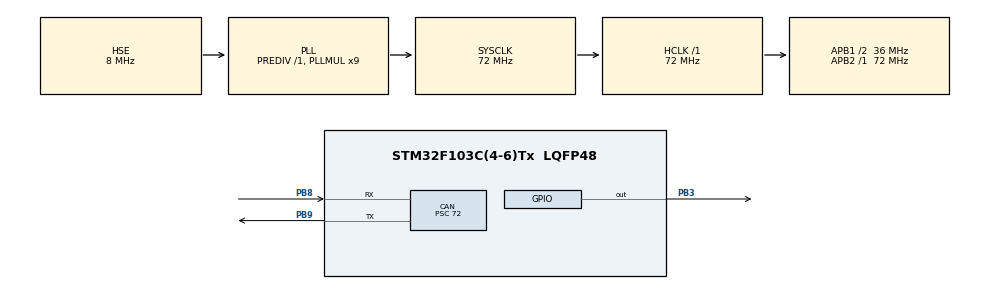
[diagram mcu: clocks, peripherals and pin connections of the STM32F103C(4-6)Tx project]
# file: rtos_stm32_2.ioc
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CAN.BS1=CAN_BS1_2TQ
CAN.CalculateBaudRate=125000
CAN.CalculateTimeBit=8000
CAN.CalculateTimeQuantum=2000.0
CAN.Prescaler=72
FREERTOS.Tasks01=receiveuart,0,128,CAN_Receive_Task,Default,NULL,Dynamic,NULL,NULL;relay2Task,0,128,Task_Relay2_Control,Default,NULL,Dynamic,NULL,NULL
FREERTOS.configUSE_NEWLIB_REENTRANT=1
Mcu.Family=STM32F1
Mcu.Name=STM32F103C(4-6)Tx
Mcu.Package=LQFP48
NVIC.CAN1_RX1_IRQn=true\:5\:0\:false\:false\:true\:true\:true\:true\:true
NVIC.PriorityGroup=NVIC_PRIORITYGROUP_4
NVIC.TIM2_IRQn=true\:15\:0\:false\:false\:true\:false\:false\:true\:true
NVIC.TimeBase=TIM2_IRQn
NVIC.TimeBaseIP=TIM2
PA13.Mode=Serial_Wire
PA13.Signal=SYS_JTMS-SWDIO
PA14.Mode=Serial_Wire
PA14.Signal=SYS_JTCK-SWCLK
PB3.Signal=GPIO_Output
PB8.Mode=CAN_Activate
PB8.Signal=CAN_RX
PB9.Mode=CAN_Activate
PB9.Signal=CAN_TX
PD0-OSC_IN.Mode=HSE-External-Oscillator
PD0-OSC_IN.Signal=RCC_OSC_IN
PD1-OSC_OUT.Mode=HSE-External-Oscillator
PD1-OSC_OUT.Signal=RCC_OSC_OUT
ProjectManager.HeapSize=0x200
ProjectManager.StackSize=0x400
ProjectManager.TargetToolchain=STM32CubeIDE
RCC.AHBFreq_Value=72000000
RCC.APB1CLKDivider=RCC_HCLK_DIV2
RCC.APB1Freq_Value=36000000
RCC.APB1TimFreq_Value=72000000
RCC.APB2Freq_Value=72000000
RCC.APB2TimFreq_Value=72000000
RCC.HCLKFreq_Value=72000000
RCC.PLLMUL=RCC_PLL_MUL9
RCC.PLLSourceVirtual=RCC_PLLSOURCE_HSE
RCC.SYSCLKFreq_VALUE=72000000
RCC.SYSCLKSource=RCC_SYSCLKSOURCE_PLLCLK
RCC.USBFreq_Value=72000000
VP_FREERTOS_VS_CMSIS_V1.Mode=CMSIS_V1
VP_SYS_VS_tim2.Mode=TIM2
board=custom

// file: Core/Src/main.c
/* USER CODE BEGIN Header */
/**
  ******************************************************************************
  * @file           : main.c
  * @brief          : Main program body
  ******************************************************************************
  * @attention
  *
  * Copyright (c) 2025 STMicroelectronics.
  * All rights reserved.
  *
  * This software is licensed under terms that can be found in the LICENSE file
  * in the root directory of this software component.
  * If no LICENSE file comes with this software, it is provided AS-IS.
  *
  ******************************************************************************
  */
/* USER CODE END Header */
#include "main.h"
#include "cmsis_os.h"
#include <string.h>

CAN_HandleTypeDef hcan;

osThreadId receiveuartHandle;
osThreadId relay2TaskHandle;
/* USER CODE BEGIN PV */
QueueHandle_t CAN_Queue;
QueueHandle_t Relay2_Queue;
/* USER CODE END PV */

void SystemClock_Config(void);
static void MX_GPIO_Init(void);
static void MX_CAN_Init(void);
void CAN_Receive_Task(void const * argument);
void Task_Relay2_Control(void const * argument);

/* USER CODE BEGIN 0 */
CAN_FilterTypeDef sFilterConfig;
CAN_RxHeaderTypeDef RxHeader;
uint8_t RxData[8];

/* Callback: CAN nhận dữ liệu */
void HAL_CAN_RxFifo1MsgPendingCallback(CAN_HandleTypeDef *hcan)
{
    if (HAL_CAN_GetRxMessage(hcan, CAN_RX_FIFO1, &RxHeader, RxData) == HAL_OK)
    {
    	BaseType_t xHigherPriorityTaskWoken = pdFALSE;
    	        xQueueSendFromISR(CAN_Queue, &RxData[0], &xHigherPriorityTaskWoken);
    	        portYIELD_FROM_ISR(xHigherPriorityTaskWoken);
    }
}
/* USER CODE END 0 */

int main(void)
{

  /* MCU Configuration--------------------------------------------------------*/

  /* Reset of all peripherals, Initializes the Flash interface and the Systick. */
  HAL_Init();

  /* Configure the system clock */
  SystemClock_Config();

  /* Initialize all configured peripherals */
  MX_GPIO_Init();
  MX_CAN_Init();
  /* USER CODE BEGIN 2 */
  HAL_GPIO_WritePin(GPIOB, GPIO_PIN_3, GPIO_PIN_SET);
  /* Khởi động CAN */
   HAL_CAN_Start(&hcan);

   /* Cấu hình bộ lọc CAN */
   sFilterConfig.FilterActivation = CAN_FILTER_ENABLE;
   sFilterConfig.FilterFIFOAssignment = CAN_FILTER_FIFO1;
   sFilterConfig.FilterMode = CAN_FILTERMODE_IDMASK;
   sFilterConfig.FilterIdHigh = 0;
   sFilterConfig.FilterIdLow = 0;
   sFilterConfig.FilterMaskIdHigh = 0;
   sFilterConfig.FilterMaskIdLow = 0;
   sFilterConfig.FilterScale = CAN_FILTERSCALE_32BIT;
   HAL_CAN_ConfigFilter(&hcan, &sFilterConfig);

   /* Kích hoạt ngắt CAN */
   HAL_CAN_ActivateNotification(&hcan, CAN_IT_RX_FIFO1_MSG_PENDING);
  /* USER CODE END 2 */

  /* USER CODE BEGIN RTOS_MUTEX */
   CAN_Queue = xQueueCreate(10, sizeof(uint8_t));
       Relay2_Queue = xQueueCreate(10, sizeof(uint8_t));
  /* add mutexes, ... */
  /* USER CODE END RTOS_MUTEX */

  /* Create the thread(s) */
  /* definition and creation of receiveuart */
  osThreadDef(receiveuart, CAN_Receive_Task, osPriorityNormal, 0, 128);
  receiveuartHandle = osThreadCreate(osThread(receiveuart), NULL);

  /* definition and creation of relay2Task */
  osThreadDef(relay2Task, Task_Relay2_Control, osPriorityNormal, 0, 128);
  relay2TaskHandle = osThreadCreate(osThread(relay2Task), NULL);

  /* Start scheduler */
  osKernelStart();

  /* We should never get here as control is now taken by the scheduler */

  /* Infinite loop */
  while (1)
  {

  }
}

void SystemClock_Config(void)
{
  RCC_OscInitTypeDef RCC_OscInitStruct = {0};
  RCC_ClkInitTypeDef RCC_ClkInitStruct = {0};

  /** Initializes the RCC Oscillators according to the specified parameters
  * in the RCC_OscInitTypeDef structure.
  */
  RCC_OscInitStruct.OscillatorType = RCC_OSCILLATORTYPE_HSE;
  RCC_OscInitStruct.HSEState = RCC_HSE_ON;
  RCC_OscInitStruct.HSEPredivValue = RCC_HSE_PREDIV_DIV1;
  RCC_OscInitStruct.HSIState = RCC_HSI_ON;
  RCC_OscInitStruct.PLL.PLLState = RCC_PLL_ON;
  RCC_OscInitStruct.PLL.PLLSource = RCC_PLLSOURCE_HSE;
  RCC_OscInitStruct.PLL.PLLMUL = RCC_PLL_MUL9;
  if (HAL_RCC_OscConfig(&RCC_OscInitStruct) != HAL_OK)
  {
    Error_Handler();
  }

  /** Initializes the CPU, AHB and APB buses clocks
  */
  RCC_ClkInitStruct.ClockType = RCC_CLOCKTYPE_HCLK|RCC_CLOCKTYPE_SYSCLK
                              |RCC_CLOCKTYPE_PCLK1|RCC_CLOCKTYPE_PCLK2;
  RCC_ClkInitStruct.SYSCLKSource = RCC_SYSCLKSOURCE_PLLCLK;
  RCC_ClkInitStruct.AHBCLKDivider = RCC_SYSCLK_DIV1;
  RCC_ClkInitStruct.APB1CLKDivider = RCC_HCLK_DIV2;
  RCC_ClkInitStruct.APB2CLKDivider = RCC_HCLK_DIV1;

  if (HAL_RCC_ClockConfig(&RCC_ClkInitStruct, FLASH_LATENCY_2) != HAL_OK)
  {
    Error_Handler();
  }
}

static void MX_CAN_Init(void)
{

  hcan.Instance = CAN1;
  hcan.Init.Prescaler = 72;
  hcan.Init.Mode = CAN_MODE_NORMAL;
  hcan.Init.SyncJumpWidth = CAN_SJW_1TQ;
  hcan.Init.TimeSeg1 = CAN_BS1_2TQ;
  hcan.Init.TimeSeg2 = CAN_BS2_1TQ;
  hcan.Init.TimeTriggeredMode = DISABLE;
  hcan.Init.AutoBusOff = DISABLE;
  hcan.Init.AutoWakeUp = DISABLE;
  hcan.Init.AutoRetransmission = DISABLE;
  hcan.Init.ReceiveFifoLocked = DISABLE;
  hcan.Init.TransmitFifoPriority = DISABLE;
  if (HAL_CAN_Init(&hcan) != HAL_OK)
  {
    Error_Handler();
  }

}

static void MX_GPIO_Init(void)
{
  GPIO_InitTypeDef GPIO_InitStruct = {0};

  /* GPIO Ports Clock Enable */
  __HAL_RCC_GPIOD_CLK_ENABLE();
  __HAL_RCC_GPIOA_CLK_ENABLE();
  __HAL_RCC_GPIOB_CLK_ENABLE();

  /*Configure GPIO pin Output Level */
  HAL_GPIO_WritePin(GPIOB, GPIO_PIN_3, GPIO_PIN_RESET);

  /*Configure GPIO pin : PB3 */
  GPIO_InitStruct.Pin = GPIO_PIN_3;
  GPIO_InitStruct.Mode = GPIO_MODE_OUTPUT_PP;
  GPIO_InitStruct.Pull = GPIO_NOPULL;
  GPIO_InitStruct.Speed = GPIO_SPEED_FREQ_LOW;
  HAL_GPIO_Init(GPIOB, &GPIO_InitStruct);

}

void CAN_Receive_Task(void const * argument)
{
	 uint8_t receivedData;
	    for (;;) {
	        if (xQueueReceive(CAN_Queue, &receivedData, portMAX_DELAY) == pdPASS) {
	            xQueueSend(Relay2_Queue, &receivedData, portMAX_DELAY);
	        }
	    }
}

void Task_Relay2_Control(void const * argument)
{
	uint8_t command;
		    for (;;) {
		        if (xQueueReceive(Relay2_Queue, &command, portMAX_DELAY) == pdPASS) {
		            if (command == '1') {
		                HAL_GPIO_WritePin(GPIOB, GPIO_PIN_3, GPIO_PIN_SET);
		            } else if (command == '2') {
		                HAL_GPIO_WritePin(GPIOB, GPIO_PIN_3, GPIO_PIN_RESET);
		            }
		        }
		    }
}

void HAL_TIM_PeriodElapsedCallback(TIM_HandleTypeDef *htim)
{
  if (htim->Instance == TIM2) {
    HAL_IncTick();
  }
}

void Error_Handler(void)
{
  __disable_irq();
  while (1)
  {
  }
}
